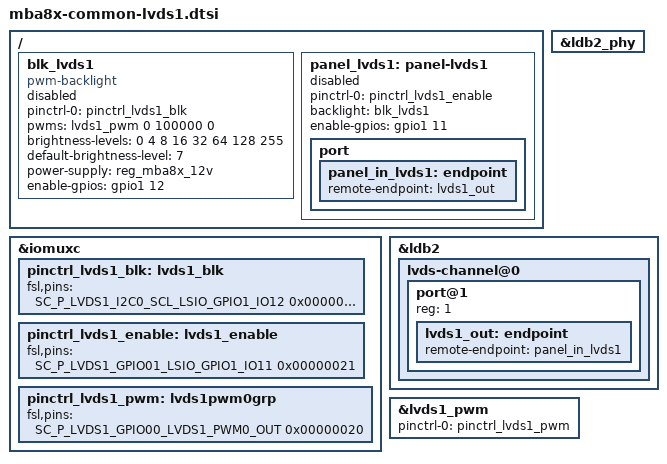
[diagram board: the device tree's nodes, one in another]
/*
 * Copyright 2018-2019 TQ Systems GmbH
 *
 * This program is free software; you can redistribute it and/or
 * modify it under the terms of the GNU General Public License
 * as published by the Free Software Foundation; either version 2
 * of the License, or (at your option) any later version.
 *
 * This program is distributed in the hope that it will be useful,
 * but WITHOUT ANY WARRANTY; without even the implied warranty of
 * MERCHANTABILITY or FITNESS FOR A PARTICULAR PURPOSE.  See the
 * GNU General Public License for more details.
 */

#include "mba8x-common-drm.dtsi"

/ {
	blk_lvds1: blk_lvds1 {

		compatible = "pwm-backlight";
		pinctrl-names = "default";
		pinctrl-0 = <&pinctrl_lvds1_blk>;
		pwms = <&lvds1_pwm 0 100000 0>;
		brightness-levels = <0 4 8 16 32 64 128 255>;
		default-brightness-level = <7>;
		power-supply = <&reg_mba8x_12v>;
		enable-gpios = <&gpio1 12 GPIO_ACTIVE_HIGH>;
		status = "disabled";
	};

	panel_lvds1: panel-lvds1 {
		pinctrl-names = "default";
		pinctrl-0 = <&pinctrl_lvds1_enable>;
		backlight = <&blk_lvds1>;
		enable-gpios = <&gpio1 11 GPIO_ACTIVE_HIGH>;
		status = "disabled";

		port {
			panel_in_lvds1: endpoint {
				remote-endpoint = <&lvds1_out>;
			};
		};
	};
};

&iomuxc {
	pinctrl_lvds1_blk: lvds1_blk {
		fsl,pins = <
			SC_P_LVDS1_I2C0_SCL_LSIO_GPIO1_IO12	0x00000021
		>;
	};

	pinctrl_lvds1_enable: lvds1_enable {
		fsl,pins = <
			SC_P_LVDS1_GPIO01_LSIO_GPIO1_IO11	0x00000021
		>;
	};

	pinctrl_lvds1_pwm: lvds1pwm0grp {
		fsl,pins = <
			SC_P_LVDS1_GPIO00_LVDS1_PWM0_OUT	0x00000020
		>;
	};
};

&ldb2_phy {
	status = "okay";
};

&ldb2 {
	lvds-channel@0 {
		status = "okay";

		port@1 {
			reg = <1>;

			lvds1_out: endpoint {
				remote-endpoint = <&panel_in_lvds1>;
			};
		};
	};
};

&lvds1_pwm {
	pinctrl-names = "default";
	pinctrl-0 = <&pinctrl_lvds1_pwm>;
	status = "okay";
};

